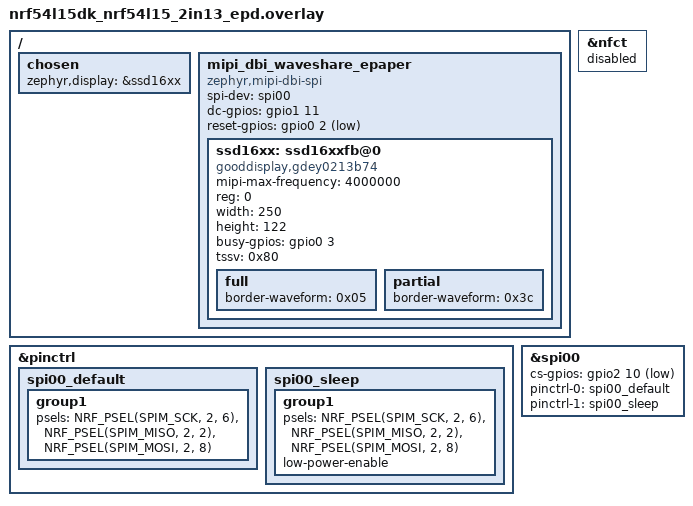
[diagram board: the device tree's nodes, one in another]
#include "nrf54l15dk_nrf54l15_memory.dtsi"

/ {
	chosen {
		zephyr,display = &ssd16xx;
	};

	mipi_dbi_waveshare_epaper {
		compatible = "zephyr,mipi-dbi-spi";
		spi-dev = <&spi00>;
		dc-gpios = <&gpio1 11 GPIO_ACTIVE_HIGH>;
		reset-gpios = <&gpio0 2 GPIO_ACTIVE_LOW>;
		#address-cells = <1>;
		#size-cells = <0>;

		ssd16xx: ssd16xxfb@0 {
			compatible = "gooddisplay,gdey0213b74", "solomon,ssd1680";
			mipi-max-frequency = <4000000>;
			reg = <0>;
			width = <250>;
			height = <122>;
			busy-gpios = <&gpio0 3 GPIO_ACTIVE_HIGH>;

			tssv = <0x80>;

			full {
				border-waveform = <0x05>;
			};

			partial {
				border-waveform = <0x3c>;
			};
		};
	};

};

&nfct {
	status = "disabled";
};

&pinctrl {
	spi00_default: spi00_default {
		group1 {
			// nordic,drive-mode = <NRF_DRIVE_H0H1>;
			psels = <NRF_PSEL(SPIM_SCK, 2, 6)>,
			        <NRF_PSEL(SPIM_MISO, 2, 2)>,
			        <NRF_PSEL(SPIM_MOSI, 2, 8)>;
		};
	};

	spi00_sleep: spi00_sleep {
		group1 {
			psels = <NRF_PSEL(SPIM_SCK, 2, 6)>,
			        <NRF_PSEL(SPIM_MISO, 2, 2)>,
			        <NRF_PSEL(SPIM_MOSI, 2, 8)>;
			low-power-enable;
		};
	};

};

&spi00 {
	status = "okay";
	cs-gpios = <&gpio2 10 GPIO_ACTIVE_LOW>;
	pinctrl-0 = <&spi00_default>;
	pinctrl-1 = <&spi00_sleep>;
	pinctrl-names = "default", "sleep";
};
